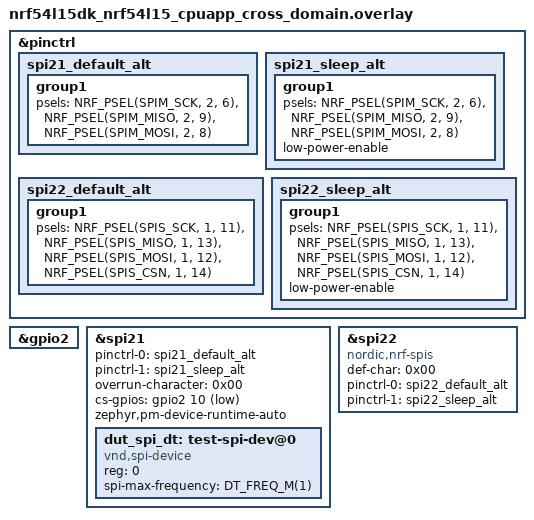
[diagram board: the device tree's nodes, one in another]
/*
 * Copyright (c) 2025 Nordic Semiconductor
 *
 * SPDX-License-Identifier: Apache-2.0
 */

&pinctrl {
	spi21_default_alt: spi21_default_alt {
		group1 {
			psels = <NRF_PSEL(SPIM_SCK, 2, 6)>,
				<NRF_PSEL(SPIM_MISO, 2, 9)>,
				<NRF_PSEL(SPIM_MOSI, 2, 8)>;
		};
	};

	spi21_sleep_alt: spi21_sleep_alt {
		group1 {
			psels = <NRF_PSEL(SPIM_SCK, 2, 6)>,
				<NRF_PSEL(SPIM_MISO, 2, 9)>,
				<NRF_PSEL(SPIM_MOSI, 2, 8)>;
			low-power-enable;
		};
	};

	spi22_default_alt: spi22_default_alt {
		group1 {
			psels = <NRF_PSEL(SPIS_SCK, 1, 11)>,
				<NRF_PSEL(SPIS_MISO, 1, 13)>,
				<NRF_PSEL(SPIS_MOSI, 1, 12)>,
				<NRF_PSEL(SPIS_CSN, 1, 14)>;
		};
	};

	spi22_sleep_alt: spi22_sleep_alt {
		group1 {
			psels = <NRF_PSEL(SPIS_SCK, 1, 11)>,
				<NRF_PSEL(SPIS_MISO, 1, 13)>,
				<NRF_PSEL(SPIS_MOSI, 1, 12)>,
				<NRF_PSEL(SPIS_CSN, 1, 14)>;
			low-power-enable;
		};
	};
};

&gpio2 {
	status = "okay";
};

&spi21 {
	status = "okay";
	pinctrl-0 = <&spi21_default_alt>;
	pinctrl-1 = <&spi21_sleep_alt>;
	pinctrl-names = "default", "sleep";
	overrun-character = <0x00>;
	cs-gpios = <&gpio2 10 GPIO_ACTIVE_LOW>;
	zephyr,pm-device-runtime-auto;
	dut_spi_dt: test-spi-dev@0 {
		compatible = "vnd,spi-device";
		reg = <0>;
		spi-max-frequency = <DT_FREQ_M(1)>;
	};
};

dut_spis: &spi22 {
	compatible = "nordic,nrf-spis";
	status = "okay";
	def-char = <0x00>;
	pinctrl-0 = <&spi22_default_alt>;
	pinctrl-1 = <&spi22_sleep_alt>;
	pinctrl-names = "default", "sleep";
	/delete-property/ rx-delay-supported;
	/delete-property/ rx-delay;
};
